# STM32F301x8 register map
File version: 1.0
Registers are 32-bit, read-write, reset 0x0 unless marked. A register's access mark holds for its fields unless they carry their own. Offsets are from the block's base; [hi:lo] are bit positions; lines under a group give offsets from that group; {n}, {i} and the like mark numbered series.

## ADC1 — Analog to Digital Converter
Base 0x50000000
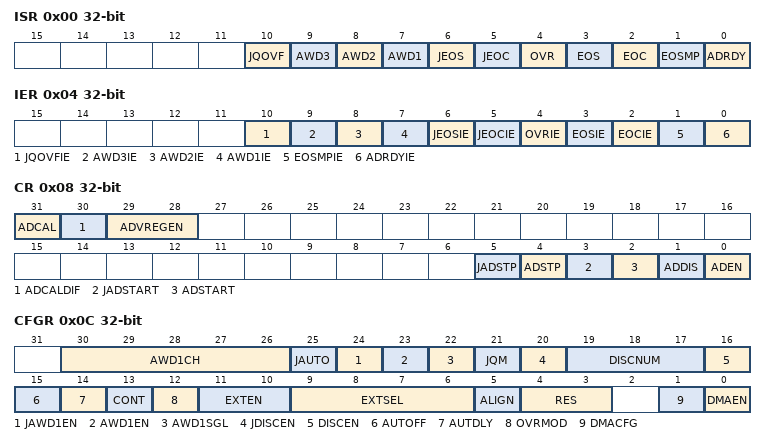
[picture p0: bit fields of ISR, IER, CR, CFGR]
0x00 ISR — ADC Interrupt and Status Register
  [10] JQOVF — ADC group injected contexts queue overflow flag
  [9] AWD3 — ADC analog watchdog 3 flag
  [8] AWD2 — ADC analog watchdog 2 flag
  [7] AWD1 — ADC analog watchdog 1 flag
  [6] JEOS — ADC group injected end of sequence conversions flag
  [5] JEOC — ADC group injected end of unitary conversion flag
  [4] OVR — ADC group regular overrun flag
  [3] EOS — ADC group regular end of sequence conversions flag
  [2] EOC — ADC group regular end of unitary conversion flag
  [1] EOSMP — ADC group regular end of sampling flag
  [0] ADRDY — ADC ready flag
0x04 IER — ADC Interrupt Enable Register
  [10] JQOVFIE — ADC group injected contexts queue overflow interrupt
  [9] AWD3IE — ADC analog watchdog 3 interrupt
  [8] AWD2IE — ADC analog watchdog 2 interrupt
  [7] AWD1IE — ADC analog watchdog 1 interrupt
  [6] JEOSIE — ADC group injected end of sequence conversions interrupt
  [5] JEOCIE — ADC group injected end of unitary conversion interrupt
  [4] OVRIE — ADC group regular overrun interrupt
  [3] EOSIE — ADC group regular end of sequence conversions interrupt
  [2] EOCIE — ADC group regular end of unitary conversion interrupt
  [1] EOSMPIE — ADC group regular end of sampling interrupt
  [0] ADRDYIE — ADC ready interrupt
0x08 CR — ADC control register
  [31] ADCAL — ADC calibration
  [30] ADCALDIF — ADC differential mode for calibration
  [29:28] ADVREGEN — ADC voltage regulator enable
  [5] JADSTP — ADC group injected conversion stop
  [4] ADSTP — ADC group regular conversion stop
  [3] JADSTART — ADC group injected conversion start
  [2] ADSTART — ADC group regular conversion start
  [1] ADDIS — ADC disable
  [0] ADEN — ADC enable
0x0C CFGR — ADC Configuration register
  [30:26] AWD1CH — ADC analog watchdog 1 monitored channel selection
  [25] JAUTO — ADC group injected automatic trigger mode
    0=INDEPENDENT (ADC group injected conversion trigger independent. Setting mandatory if ADC group injected injected trigger source is set to an external trigger.); 1=FROM_GRP_REGULAR (ADC group injected conversion trigger from ADC group regular. Setting compliant only with group injected trigger source set to SW start, without any further action on ADC group injected conversion start or stop: in this case, ADC group injected is controlled only from ADC group regular.)
  [24] JAWD1EN — ADC analog watchdog 1 enable on scope ADC group injected
  [23] AWD1EN — ADC analog watchdog 1 enable on scope ADC group regular
  [22] AWD1SGL — ADC analog watchdog 1 monitoring a single channel or all channels
  [21] JQM — ADC group injected contexts queue mode
    0=LAST_ACTIVE; 1=END_EMPTY
  [20] JDISCEN — ADC Discontinuous mode on injected channels
    0=DISABLE (ADC group injected sequencer discontinuous mode disable); 1=DISCONT_1RANK (ADC group injected sequencer discontinuous mode enable with sequence interruption every rank)
  [19:17] DISCNUM — ADC Discontinuous mode channel count
  [16] DISCEN — ADC group regular sequencer discontinuous mode
  [15] AUTOFF — ADC low power auto power off
  [14] AUTDLY — ADC low power auto wait
    0=MODE_NONE (No ADC low power mode activated); 1=AUTOWAIT (ADC low power mode auto delay: Dynamic low power mode, ADC conversions are performed only when necessary (when previous ADC conversion data is read). See description with function @ref LL_ADC_SetLowPowerMode().)
  [13] CONT — ADC group regular continuous conversion mode
    0=SINGLE (ADC conversions are performed in single mode: one conversion per trigger); 1=CONTINUOUS (ADC conversions are performed in continuous mode: after the first trigger, following conversions launched successively automatically)
  [12] OVRMOD — ADC group regular overrun configuration
    0=PRESERVED (ADC group regular behavior in case of overrun: data preserved); 1=OVERWRITTEN (ADC group regular behavior in case of overrun: data overwritten)
  [11:10] EXTEN — ADC group regular external trigger polarity
    1=RISING (ADC group regular conversion trigger polarity set to rising edge); 2=FALLING (ADC group regular conversion trigger polarity set to falling edge); 3=RISINGFALLING (ADC group regular conversion trigger polarity set to both rising and falling edges)
  [9:6] EXTSEL — ADC group regular external trigger source
  [5] ALIGN — ADC data alignment
    0=RIGHT (ADC conversion data alignment: right aligned (alignment on data register LSB bit 0)); 1=LEFT (ADC conversion data alignment: left aligned (alignment on data register MSB bit 15))
  [4:3] RES — ADC data resolution
    0=RESOLUTION_12B (ADC resolution 12 bits); 1=RESOLUTION_10B (ADC resolution 10 bits); 2=RESOLUTION_8B (ADC resolution 8 bits); 3=RESOLUTION_6B (ADC resolution 6 bits)
  [1] DMACFG — ADC DMA configuration
  [0] DMAEN — ADC DMA enable
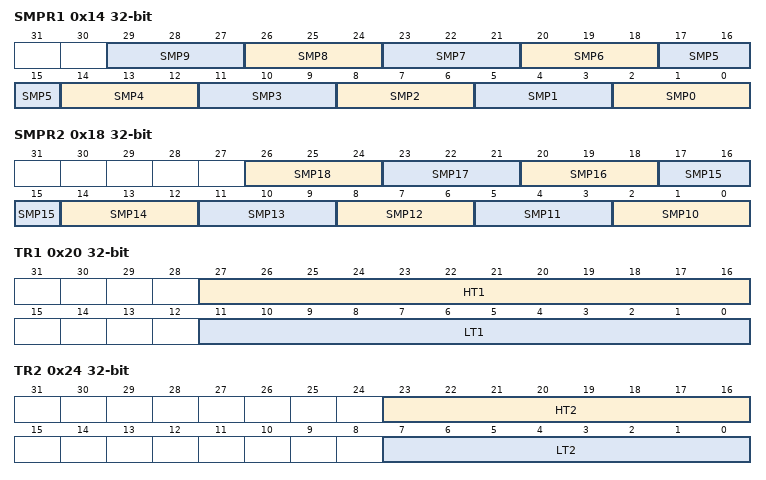
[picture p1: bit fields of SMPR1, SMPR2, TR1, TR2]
0x14 SMPR1 — ADC sample time register 1
  [3n+2:3n] SMP{n} (n=0..9) — ADC channel {n} sampling time selection
0x18 SMPR2 — ADC sample time register 2
  [3n-28:3n-30] SMP{n} (n=10..18) — ADC channel {n} sampling time selection
0x20 TR1 — ADC watchdog threshold register 1
  [27:16] HT1 — ADC Analog watchdog 1 threshold high
  [11:0] LT1 — ADC analog watchdog 1 threshold low
0x24 TR2 — ADC watchdog threshold register 2
  [23:16] HT2 — ADC analog watchdog 2 threshold high
  [7:0] LT2 — ADC analog watchdog 2 threshold low
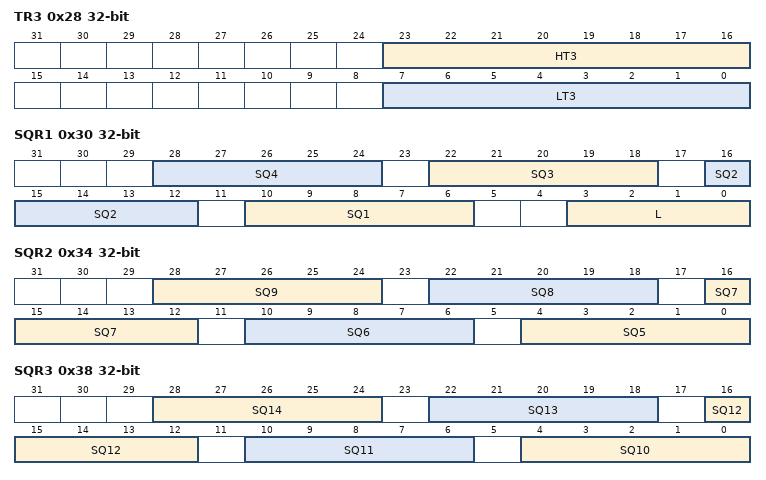
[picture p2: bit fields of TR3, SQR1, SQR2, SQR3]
0x28 TR3 — ADC watchdog threshold register 3
  [23:16] HT3 — ADC analog watchdog 3 threshold high
  [7:0] LT3 — ADC analog watchdog 3 threshold low
0x30 SQR1 — ADC regular sequence register 1
  [6n+4:6n] SQ{n} (n=1..4) — ADC group regular sequencer rank {n}
  [3:0] L — ADC group regular sequencer scan length
    0=DISABLE (ADC group regular sequencer disable (equivalent to sequencer of 1 rank: ADC conversion on only 1 channel)); {v}=ENABLE_{v+1}RANKS (ADC group regular sequencer enable with {v+1} ranks in the sequence) (v=1..15)
0x34 SQR2 — ADC regular sequence register 2
  [6n-26:6n-30] SQ{n} (n=5..9) — ADC group regular sequencer rank {n}
0x38 SQR3 — ADC regular sequence register 3
  [6n-56:6n-60] SQ{n} (n=10..14) — ADC group regular sequencer rank {n}
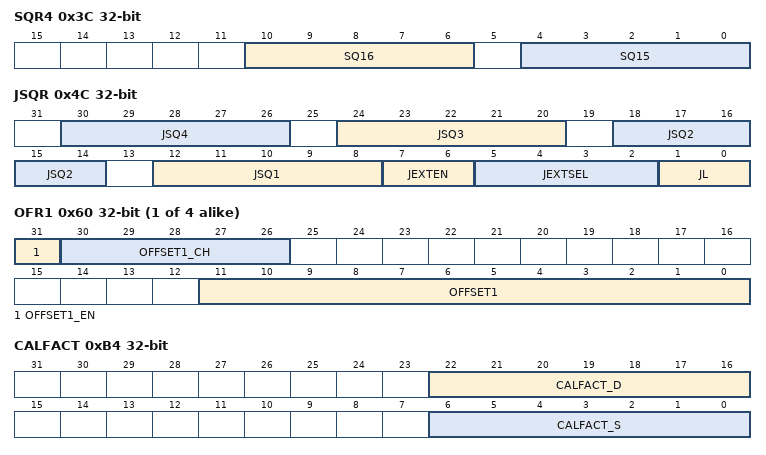
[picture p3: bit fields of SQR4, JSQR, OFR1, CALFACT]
0x3C SQR4 — ADC regular sequence register 4
  [10:6] SQ16 — ADC group regular sequencer rank 16
  [4:0] SQ15 — ADC group regular sequencer rank 15
0x40 DR — ADC regular data register
  [15:0] RDATA — ADC group regular conversion data
0x4C JSQR — ADC injected sequence register
  [6n+6:6n+2] JSQ{n} (n=1..4) — ADC group injected sequencer rank {n}
  [7:6] JEXTEN — ADC group injected external trigger polarity
    1=RISING (ADC group injected conversion trigger polarity set to rising edge); 2=FALLING (ADC group injected conversion trigger polarity set to falling edge); 3=RISINGFALLING (ADC group injected conversion trigger polarity set to both rising and falling edges)
  [5:2] JEXTSEL — ADC group injected external trigger source
  [1:0] JL — ADC group injected sequencer scan length
    0=DISABLE (ADC group injected sequencer disable (equivalent to sequencer of 1 rank: ADC conversion on only 1 channel)); 1=ENABLE_2RANKS (ADC group injected sequencer enable with 2 ranks in the sequence); 2=ENABLE_3RANKS (ADC group injected sequencer enable with 3 ranks in the sequence); 3=ENABLE_4RANKS (ADC group injected sequencer enable with 4 ranks in the sequence)
{0x5C+4i} OFR{i} (i=1..4) — ADC
  [31] OFFSET{i}_EN — ADC offset number {i} enable
  [30:26] OFFSET{i}_CH — ADC offset number {i} channel selection
  [11:0] OFFSET{i} — ADC offset number {i} offset level
{0x7C+4i} JDR{i} (i=1..4) — ADC injected data register {i}
  [15:0] JDATA — ADC group injected sequencer rank {i} conversion data
0xA0 AWD2CR — ADC Analog Watchdog 2 Configuration Register
  [18:1] AWD2CH — ADC analog watchdog 2 monitored channel selection
0xA4 AWD3CR — ADC Analog Watchdog 3 Configuration Register
  [18:1] AWD3CH — ADC analog watchdog 3 monitored channel selection
0xB0 DIFSEL — ADC Differential Mode Selection Register
  [18:1] DIFSEL — ADC channel differential or single-ended mode
0xB4 CALFACT — ADC Calibration Factors
  [22:16] CALFACT_D — ADC calibration factor in differential mode
  [6:0] CALFACT_S — ADC calibration factor in single-ended mode
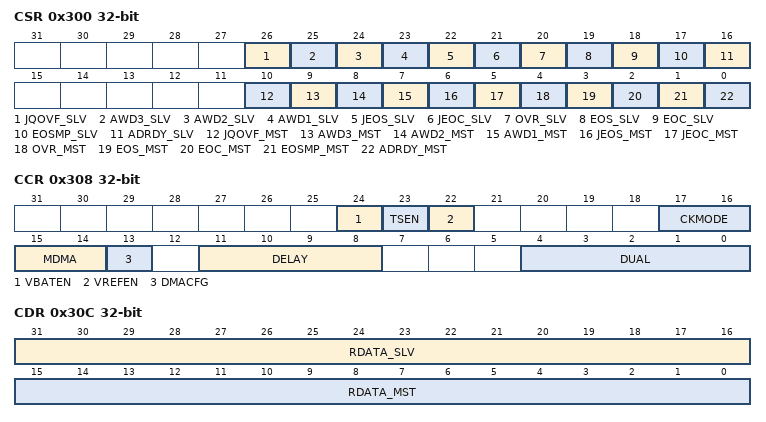
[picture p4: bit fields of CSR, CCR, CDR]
0x300 CSR — ADC Common status register
  [26] JQOVF_SLV — ADC multimode slave group injected contexts queue overflow flag
  [25] AWD3_SLV — ADC multimode slave analog watchdog 3 flag
  [24] AWD2_SLV — ADC multimode slave analog watchdog 2 flag
  [23] AWD1_SLV — ADC multimode slave analog watchdog 1 flag
  [22] JEOS_SLV — ADC multimode slave group injected end of sequence conversions flag
  [21] JEOC_SLV — ADC multimode slave group injected end of unitary conversion flag
  [20] OVR_SLV — ADC multimode slave group regular overrun flag
  [19] EOS_SLV — ADC multimode slave group regular end of sequence conversions flag
  [18] EOC_SLV — ADC multimode slave group regular end of unitary conversion flag
  [17] EOSMP_SLV — ADC multimode slave group regular end of sampling flag
  [16] ADRDY_SLV — ADC multimode slave ready flag
  [10] JQOVF_MST — ADC multimode master group injected contexts queue overflow flag
  [9] AWD3_MST — ADC multimode master analog watchdog 3 flag
  [8] AWD2_MST — ADC multimode master analog watchdog 2 flag
  [7] AWD1_MST — ADC multimode master analog watchdog 1 flag
  [6] JEOS_MST — ADC multimode master group injected end of sequence conversions flag
  [5] JEOC_MST — ADC multimode master group injected end of unitary conversion flag
  [4] OVR_MST — ADC multimode master group regular overrun flag
  [3] EOS_MST — ADC multimode master group regular end of sequence conversions flag
  [2] EOC_MST — ADC multimode master group regular end of unitary conversion flag
  [1] EOSMP_MST — ADC multimode master group regular end of sampling flag
  [0] ADRDY_MST — ADC multimode master ready flag
0x308 CCR — ADC common control register
  [24] VBATEN — ADC internal path to battery voltage enable
  [23] TSEN — ADC internal path to temperature sensor enable
  [22] VREFEN — ADC internal path to VrefInt enable
  [17:16] CKMODE — ADC common clock source and prescaler (prescaler only for clock source synchronous)
    1=SYNC_PCLK_DIV1 (ADC synchronous clock derived from AHB clock without prescaler); 2=SYNC_PCLK_DIV2 (ADC synchronous clock derived from AHB clock with prescaler division by 2); 3=SYNC_PCLK_DIV4 (ADC synchronous clock derived from AHB clock with prescaler division by 4); 0=ASYNC_DIV1 (ADC asynchronous clock without prescaler)
  [15:14] MDMA — ADC multimode DMA transfer enable
  [13] DMACFG — ADC multimode DMA transfer configuration
  [11:8] DELAY — ADC multimode delay between 2 sampling phases
  [4:0] DUAL — ADC multimode mode selection
0x30C CDR — ADC common regular data register for dual AND triple modes
  [31:16] RDATA_SLV — ADC multimode slave group regular conversion data
  [15:0] RDATA_MST — ADC multimode master group regular conversion data
